# ISD91000_v4_2 register map
File version: 1.0
Registers are 32-bit, read-write, reset 0x0 unless marked. A register's access mark holds for its fields unless they carry their own. Offsets are from the block's base; [hi:lo] are bit positions; <NAME> marks a mode.

## WDT — WDT Register Map
Base 0x40004000
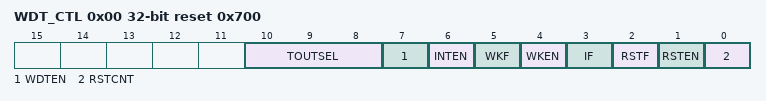
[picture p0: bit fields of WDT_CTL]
0x00 WDT_CTL reset 0x700 — Watchdog Timer Control Register
  [10:8] TOUTSEL — Watchdog Timer Interval Select. These three bits select the timeout interval for the Watchdog timer, a watchdog reset will occur 1024 clock cycles later if Watchdog timer is not reset. The WDT interrupt timeout is given by: Where WDT_CLK is the period of the Watchdog Timer clock source.
    0=24 * WDT_CLK; 1=26 * WDT_CLK; 2=28 * WDT_CLK; 3=210 * WDT_CLK; 4=212 * WDT_CLK; 5=214 * WDT_CLK; 6=216 * WDT_CLK; 7=218 * WDT_CLK
  [7] WDTEN — Watchdog Timer Enable
    0=Disable the WDT(Watchdog timer) (This action will reset the internal counter); 1=Enable the WDT(Watchdog timer)
  [6] INTEN — Watchdog Time-Out Interrupt Enable
    0=Disable the WDT time-out interrupt; 1=Enable the WDT time-out interrupt
  [5] WKF — WDT Time-Out Wake-Up Flag. If WDT causes CPU wake up from sleep or power-down mode, this bit will be set to high. Note: This bit is cleared by writing 1 to it.
    0=WDT does not cause CPU wake-up; 1=CPU wakes up from sleep or power-down mode by WDT time-out interrupt
  [4] WKEN — WDT Time-Out Wake-Up Function Control. If this bit is set to 1, while WDT time-out interrupt flag IF (WDT_CTL[3]) is generated to 1 and interrupt enable bit INTEN (WDT_CTL[6]) is enabled, the WDT time-out interrupt signal will generate a wake-up trigger event to chip.
    0=Disable WDT Wakeup CPU function; 1=Enable the Wakeup function that WDT timeout can wake up CPU from power-down mode
  [3] IF — Watchdog Timer Interrupt Flag. If the Watchdog timer interrupt is enabled, then the hardware will set this bit to indicate that the Watchdog timer interrupt has occurred. If the Watchdog timer interrupt is not enabled, then this bit indicates that a timeout period has elapsed. Note: This bit is cleared by writing 1 to this bit.
    0=Watchdog timer interrupt has not occurred; 1=Watchdog timer interrupt has occurred
  [2] RSTF — Watchdog Timer Reset Flag. When the Watchdog timer initiates a reset, the hardware will set this bit. This flag can be read by software to determine the source of reset. Software is responsible to clear it manually by writing 1 to it. If RSTEN is disabled, then the Watchdog timer has no effect on this bit. Note: This bit is cleared by writing 1 to this bit.
    0=Watchdog timer reset has not occurred; 1=Watchdog timer reset has occurred
  [1] RSTEN — Watchdog Timer Reset Enable. Setting this bit will enable the Watchdog timer reset function. Note: This function cannot work with XTL32-based clock source.
    0=Disable Watchdog timer reset function; 1=Enable Watchdog timer reset function
  [0] RSTCNT — Clear Watchdog Timer. Set this bit will clear the Watchdog timer. Note: This bit will auto clear after few clock cycles
    0=Writing 0 to this bit has no effect; 1=Reset the contents of the Watchdog timer

## PDMA_GCR — PDMA Register Map
Base 0x50009F00
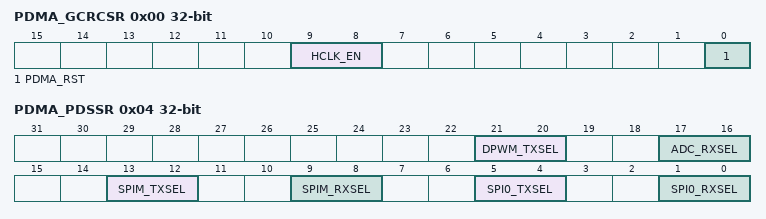
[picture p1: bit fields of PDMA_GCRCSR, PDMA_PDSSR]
0x00 PDMA_GCRCSR — PDMA Global Control Register
  [9:8] HCLK_EN — PDMA Controller Channel Clock Enable Control. To enable clock for channel n HCLK_EN[n] must be set.
  [0] PDMA_RST — PDMA Software Reset. Note: This bit can reset all channels (global reset).
    0=Writing 0 to this bit has no effect; 1=Writing 1 to this bit will reset the internal state machine and pointers. The contents of control register will not be cleared. This bit will auto clear after several clock cycles
0x04 PDMA_PDSSR — PDMA Service Selection Control Register
  [all] fields
    0=No channel select; 1=Select channel 0; 2=Select channel 1
  [21:20] DPWM_TXSEL — PDMA DPWM Transmit Selection. This field defines which PDMA channel is connected to DPWM peripheral transmit (PDMA destination) request.
  [17:16] ADC_RXSEL — PDMA ADC Receive Selection. This field defines which PDMA channel is connected to ADC peripheral receive (PDMA source) request.
  [13:12] SPIM_TXSEL — PDMA SPIM Transmit Selection. This field defines which PDMA channel is connected to SPIM peripheral transmit (PDMA destination) request.
  [9:8] SPIM_RXSEL — PDMA SPIM Receive Selection. This field defines which PDMA channel is connected to SPIM peripheral receive (PDMA source) request.
  [5:4] SPI0_TXSEL — PDMA SPI0 Transmit Selection. This field defines which PDMA channel is connected to SPI0 peripheral transmit (PDMA destination) request.
  [1:0] SPI0_RXSEL — PDMA SPI0 Receive Selection. This field defines which PDMA channel is connected to SPI0 peripheral receive (PDMA source) request.
0x0C PDMA_GCRISR ro — PDMA Global Interrupt Status Register
  [1:0] GCRISR — Interrupt Pin Status (Read Only). GCRISR[n] is the interrupt status of PDMA channel n.

## FMC — FCM Register Map
Base 0x5000C000
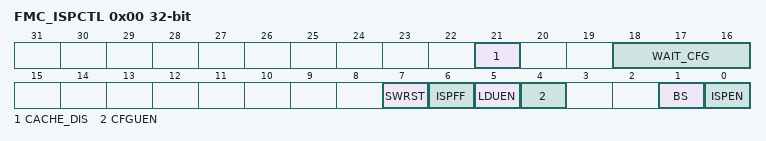
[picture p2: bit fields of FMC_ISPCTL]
0x00 FMC_ISPCTL — ISP Control Register
  [21] CACHE_DIS — Cache Disable. When set to 1, caching of flash memory reads is disabled.
  [18:16] WAIT_CFG — Flash Access Wait State Configuration. 0x11: Zero wait states. HCLK < 24MHz. 0x01: Two wait states. 0x00: Four wait state. Before changing WAIT_CFG, ensure HCLK speed is < 25MHz.
  [7] SWRST — Software Reset. Writing 1 to this bit will initiate a software reset. It is cleared by hardware after reset.
  [6] ISPFF — ISP Fail Flag. This bit is set by hardware when a triggered ISP meets any of the following conditions: (1) APROM writes to itself. (2) LDROM writes to itself. (3) Destination address is illegal, such as over an available range. Write 1 to clear.
  [5] LDUEN — LDROM Update Enable. LDROM update enable bit.
    0=LDROM cannot be updated; 1=LDROM can be updated when the MCU runs in APROM
  [4] CFGUEN — CONFIG Update Enable. When enabled, ISP functions can access the CONFIG address space and modify device configuration area.
    1=Enable, 0 = Disable
  [1] BS — Boot Select. 1: LDROM, 0: APROM. Modify this bit to select which ROM next boot is to occur. This bit also functions as MCU boot status flag, which can be used to check where MCU booted from. This bit is initialized after power-on reset with the inverse of CBS in Config0; It is not reset for any other reset event.
  [0] ISPEN — ISP Enable
    0=Disable ISP function; 1=Enable ISP function
0x04 FMC_ISPADR — ISP Address Register
  [31:0] ISPADR — ISP Address Register. This is the memory address register that a subsequent ISP command will access. ISP operation are carried out on 32bit words only, consequently ISPARD[1:0] must be 00b for correct ISP operation.
0x08 FMC_ISPDAT — ISP Data Register
  [31:0] ISPDAT — ISP Data Register. Write data to this register before an ISP program operation. Read data from this register after an ISP read operation
0x0C FMC_ISPCMD — ISP Command Register
  [5:0] ISPCMD — ISP Command
    0=Read; 11=Read CID; 12=Read DID; 33=Program; 34=Page Erase
0x10 FMC_ISPTRG — ISP Trigger Control Register
  [0] ISPGO — ISP Start Trigger. Write 1 to start ISP operation. This will be cleared to 0 by hardware automatically when ISP operation is finished. After triggering an ISP function M0 instruction pipeline should be flushed with a ISB instruction to guarantee data integrity. This is a protected register, user must first follow the unlock sequence (see Register Lock Control Register (SYS_REGLCTL)) to gain access.
    0=ISP operation is finished; 1=ISP is on going
0x14 FMC_DFBADR ro reset not defined — Data Flash Base Address Register
  [31:0] DFBA — Data Flash Base Address. This register reports the data flash starting address. It is a read only register. Data flash size is defined by user configuration, register content is loaded from Config1 when chip is reset.
